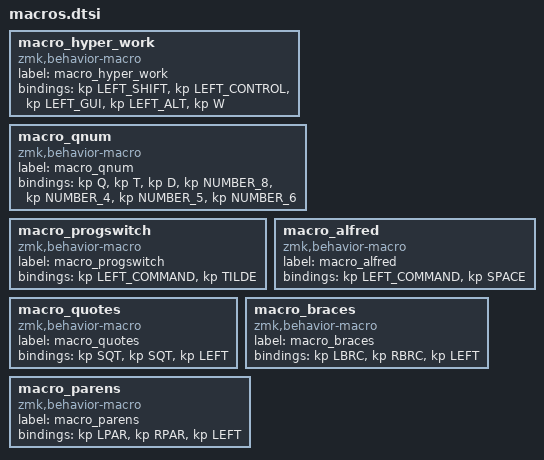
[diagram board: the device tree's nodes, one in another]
macro_hyper_work: macro_hyper_work{
compatible = "zmk,behavior-macro";
label = "macro_hyper_work";
#binding-cells = <0>;
bindings = <&kp LEFT_SHIFT>, <&kp LEFT_CONTROL>, <&kp LEFT_GUI>, <&kp LEFT_ALT>, <&kp W>;
};
macro_qnum: macro_qnum{
compatible = "zmk,behavior-macro";
label = "macro_qnum";
#binding-cells = <0>;
bindings = <&kp Q>, <&kp T>, <&kp D>, <&kp NUMBER_8>, <&kp NUMBER_4>, <&kp NUMBER_5>, <&kp NUMBER_6>;
};
macro_progswitch: macro_progswitch{
compatible = "zmk,behavior-macro";
label = "macro_progswitch";
#binding-cells = <0>;
bindings = <&kp LEFT_COMMAND>, <&kp TILDE>;
};
macro_alfred: macro_alfred{
compatible = "zmk,behavior-macro";
label = "macro_alfred";
#binding-cells = <0>;
bindings = <&kp LEFT_COMMAND>, <&kp SPACE>;
};
macro_quotes: macro_quotes{
compatible = "zmk,behavior-macro";
label = "macro_quotes";
#binding-cells = <0>;
bindings = <&kp SQT>, <&kp SQT>, <&kp LEFT>;
};
macro_braces: macro_braces{
compatible = "zmk,behavior-macro";
label = "macro_braces";
#binding-cells = <0>;
bindings = <&kp LBRC>, <&kp RBRC>, <&kp LEFT>;
};
macro_parens: macro_parens{
compatible = "zmk,behavior-macro";
label = "macro_parens";
#binding-cells = <0>;
bindings = <&kp LPAR>, <&kp RPAR>, <&kp LEFT>;
};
